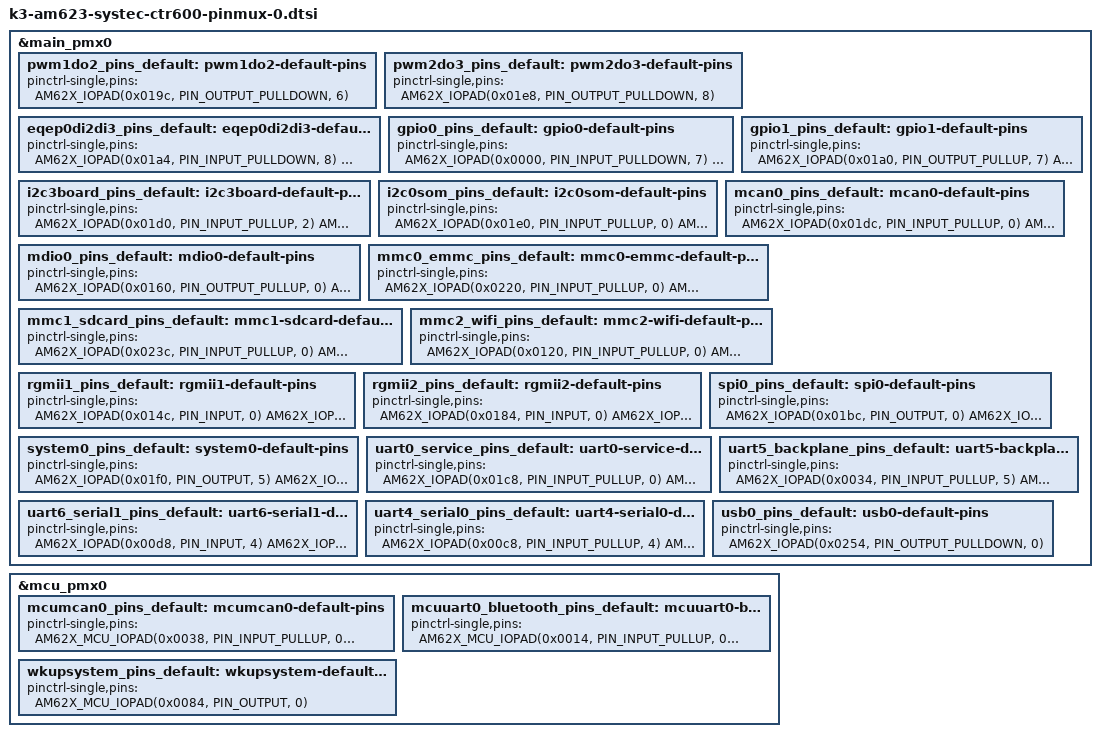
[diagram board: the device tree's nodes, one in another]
/* This file was auto-generated by TI PinMux on 17.10.2024 at 12:08:37. */
/* This file should only be used as a reference. Some pins/peripherals, */
/* depending on your use case, may need additional configuration. */

/* Some or all of the pins from the following groups are not used by the device tree
	ddr
	usb0
*/

&main_pmx0 {
	pwm1do2_pins_default: pwm1do2-default-pins {
		pinctrl-single,pins = <
			AM62X_IOPAD(0x019c, PIN_OUTPUT_PULLDOWN, 6) /* (B18) MCASP0_AXR1.EHRPWM1_A */
		>;
	};
	pwm2do3_pins_default: pwm2do3-default-pins {
		pinctrl-single,pins = <
			AM62X_IOPAD(0x01e8, PIN_OUTPUT_PULLDOWN, 8) /* (B17) I2C1_SCL.EHRPWM2_A */
		>;
	};
	eqep0di2di3_pins_default: eqep0di2di3-default-pins {
		pinctrl-single,pins = <
			AM62X_IOPAD(0x01a4, PIN_INPUT_PULLDOWN, 8) /* (B20) MCASP0_ACLKX.EQEP1_A */
			AM62X_IOPAD(0x01a8, PIN_INPUT_PULLDOWN, 8) /* (D20) MCASP0_AFSX.EQEP1_B */
		>;
	};
	gpio0_pins_default: gpio0-default-pins {
		pinctrl-single,pins = <
			AM62X_IOPAD(0x0000, PIN_INPUT_PULLDOWN, 7) /* (H24) OSPI0_CLK.GPIO0_0 */
			AM62X_IOPAD(0x0014, PIN_OUTPUT_PULLDOWN, 7) /* (F25) OSPI0_D2.GPIO0_5 */
			AM62X_IOPAD(0x0018, PIN_OUTPUT_PULLDOWN, 7) /* (F24) OSPI0_D3.GPIO0_6 */
			AM62X_IOPAD(0x001c, PIN_OUTPUT_PULLUP, 7) /* (J23) OSPI0_D4.GPIO0_7 */
			AM62X_IOPAD(0x002c, PIN_INPUT_PULLUP, 7) /* (F23) OSPI0_CSn0.GPIO0_11 */
			AM62X_IOPAD(0x0030, PIN_INPUT_PULLUP, 7) /* (G21) OSPI0_CSn1.GPIO0_12 */
			AM62X_IOPAD(0x004c, PIN_OUTPUT_PULLDOWN, 7) /* (P24) GPMC0_AD4.GPIO0_19 */
			AM62X_IOPAD(0x0050, PIN_OUTPUT_PULLDOWN, 7) /* (P22) GPMC0_AD5.GPIO0_20 */
			AM62X_IOPAD(0x0070, PIN_INPUT, 7) /* (T24) GPMC0_AD13.GPIO0_28 */
			AM62X_IOPAD(0x007c, PIN_OUTPUT, 7) /* (P25) GPMC0_CLK.GPIO0_31 */
			AM62X_IOPAD(0x0084, PIN_OUTPUT_PULLDOWN, 7) /* (L23) GPMC0_ADVn_ALE.GPIO0_32 */
			AM62X_IOPAD(0x0088, PIN_OUTPUT_PULLDOWN, 7) /* (L24) GPMC0_OEn_REn.GPIO0_33 */
			AM62X_IOPAD(0x008c, PIN_OUTPUT_PULLDOWN, 7) /* (L25) GPMC0_WEn.GPIO0_34 */
			AM62X_IOPAD(0x00b0, PIN_INPUT_PULLDOWN, 7) /* (K22) GPMC0_CSn2.GPIO0_43 */
			AM62X_IOPAD(0x00b8, PIN_INPUT_PULLDOWN, 7) /* (U22) VOUT0_DATA0.GPIO0_45 */
			AM62X_IOPAD(0x00bc, PIN_INPUT_PULLDOWN, 7) /* (V24) VOUT0_DATA1.GPIO0_46 */
			AM62X_IOPAD(0x00c0, PIN_INPUT_PULLDOWN, 7) /* (W25) VOUT0_DATA2.GPIO0_47 */
			AM62X_IOPAD(0x00c4, PIN_INPUT_PULLDOWN, 7) /* (W24) VOUT0_DATA3.GPIO0_48 */
			AM62X_IOPAD(0x00fc, PIN_INPUT_PULLUP, 7) /* (Y20) VOUT0_DE.GPIO0_62 */
			AM62X_IOPAD(0x0100, PIN_OUTPUT_PULLDOWN, 7) /* (AC25) VOUT0_VSYNC.GPIO0_63 */
			AM62X_IOPAD(0x0104, PIN_INPUT_PULLDOWN, 7) /* (AC24) VOUT0_PCLK.GPIO0_64 */
			AM62X_IOPAD(0x0124, PIN_OUTPUT_PULLDOWN, 7) /* (A23) MMC2_SDCD.GPIO0_71 */
			AM62X_IOPAD(0x0128, PIN_OUTPUT_PULLDOWN, 7) /* (B23) MMC2_SDWP.GPIO0_72 */
		>;
	};
	gpio1_pins_default: gpio1-default-pins {
		pinctrl-single,pins = <
			AM62X_IOPAD(0x01a0, PIN_OUTPUT_PULLUP, 7) /* (E18) MCASP0_AXR0.GPIO1_10 */
			AM62X_IOPAD(0x01b4, PIN_OUTPUT_PULLUP, 7) /* (A13) SPI0_CS0.GPIO1_15 */
			AM62X_IOPAD(0x01ec, PIN_OUTPUT_PULLUP, 7) /* (A17) I2C1_SDA.GPIO1_29 */
			AM62X_IOPAD(0x0244, PIN_OUTPUT_PULLDOWN, 7) /* (C17) MMC1_SDWP.GPIO1_49 */
			AM62X_IOPAD(0x0258, PIN_OUTPUT_PULLDOWN, 7) /* (F18) USB1_DRVVBUS.GPIO1_51 */
		>;
	};
	i2c3board_pins_default: i2c3board-default-pins {
		pinctrl-single,pins = <
			AM62X_IOPAD(0x01d0, PIN_INPUT_PULLUP, 2) /* (A15) UART0_CTSn.I2C3_SCL */
			AM62X_IOPAD(0x01d4, PIN_INPUT_PULLUP, 2) /* (B15) UART0_RTSn.I2C3_SDA */
		>;
	};
	i2c0som_pins_default: i2c0som-default-pins {
		pinctrl-single,pins = <
			AM62X_IOPAD(0x01e0, PIN_INPUT_PULLUP, 0) /* (B16) I2C0_SCL */
			AM62X_IOPAD(0x01e4, PIN_INPUT_PULLUP, 0) /* (A16) I2C0_SDA */
		>;
	};
	mcan0_pins_default: mcan0-default-pins {
		pinctrl-single,pins = <
			AM62X_IOPAD(0x01dc, PIN_INPUT_PULLUP, 0) /* (E15) MCAN0_RX */
			AM62X_IOPAD(0x01d8, PIN_OUTPUT, 0) /* (C15) MCAN0_TX */
		>;
	};
	mdio0_pins_default: mdio0-default-pins {
		pinctrl-single,pins = <
			AM62X_IOPAD(0x0160, PIN_OUTPUT_PULLUP, 0) /* (AD24) MDIO0_MDC */
			AM62X_IOPAD(0x015c, PIN_INPUT_PULLUP, 0) /* (AB22) MDIO0_MDIO */
		>;
	};
	mmc0_emmc_pins_default: mmc0-emmc-default-pins {
		pinctrl-single,pins = <
			AM62X_IOPAD(0x0220, PIN_INPUT_PULLUP, 0) /* (Y3) MMC0_CMD */
			AM62X_IOPAD(0x0218, PIN_OUTPUT, 0) /* (AB1) MMC0_CLK */
			AM62X_IOPAD(0x0214, PIN_INPUT_PULLUP, 0) /* (AA2) MMC0_DAT0 */
			AM62X_IOPAD(0x0210, PIN_INPUT_PULLUP, 0) /* (AA1) MMC0_DAT1 */
			AM62X_IOPAD(0x020c, PIN_INPUT_PULLUP, 0) /* (AA3) MMC0_DAT2 */
			AM62X_IOPAD(0x0208, PIN_INPUT_PULLUP, 0) /* (Y4) MMC0_DAT3 */
			AM62X_IOPAD(0x0204, PIN_INPUT_PULLUP, 0) /* (AB2) MMC0_DAT4 */
			AM62X_IOPAD(0x0200, PIN_INPUT_PULLUP, 0) /* (AC1) MMC0_DAT5 */
			AM62X_IOPAD(0x01fc, PIN_INPUT_PULLUP, 0) /* (AD2) MMC0_DAT6 */
			AM62X_IOPAD(0x01f8, PIN_INPUT_PULLUP, 0) /* (AC2) MMC0_DAT7 */
		>;
	};
	mmc1_sdcard_pins_default: mmc1-sdcard-default-pins {
		pinctrl-single,pins = <
			AM62X_IOPAD(0x023c, PIN_INPUT_PULLUP, 0) /* (A21) MMC1_CMD */
			AM62X_IOPAD(0x0234, PIN_OUTPUT, 0) /* (B22) MMC1_CLK */
			AM62X_IOPAD(0x0230, PIN_INPUT_PULLUP, 0) /* (A22) MMC1_DAT0 */
			AM62X_IOPAD(0x022c, PIN_INPUT_PULLUP, 0) /* (B21) MMC1_DAT1 */
			AM62X_IOPAD(0x0228, PIN_INPUT_PULLUP, 0) /* (C21) MMC1_DAT2 */
			AM62X_IOPAD(0x0224, PIN_INPUT_PULLUP, 0) /* (D22) MMC1_DAT3 */
			AM62X_IOPAD(0x0240, PIN_INPUT_PULLUP, 0) /* (D17) MMC1_SDCD */
		>;
	};
	mmc2_wifi_pins_default: mmc2-wifi-default-pins {
		pinctrl-single,pins = <
			AM62X_IOPAD(0x0120, PIN_INPUT_PULLUP, 0) /* (C24) MMC2_CMD */
			AM62X_IOPAD(0x0118, PIN_OUTPUT, 0) /* (D25) MMC2_CLK */
			AM62X_IOPAD(0x011C, PIN_INPUT, 0) /* () MMC2_CLKLB */
			AM62X_IOPAD(0x0114, PIN_INPUT_PULLUP, 0) /* (B24) MMC2_DAT0 */
			AM62X_IOPAD(0x0110, PIN_INPUT_PULLUP, 0) /* (C25) MMC2_DAT1 */
			AM62X_IOPAD(0x010c, PIN_INPUT_PULLUP, 0) /* (E23) MMC2_DAT2 */
			AM62X_IOPAD(0x0108, PIN_INPUT_PULLUP, 0) /* (D24) MMC2_DAT3 */
		>;
	};
	rgmii1_pins_default: rgmii1-default-pins {
		pinctrl-single,pins = <
			AM62X_IOPAD(0x014c, PIN_INPUT, 0) /* (AB17) RGMII1_RD0 */
			AM62X_IOPAD(0x0150, PIN_INPUT, 0) /* (AC17) RGMII1_RD1 */
			AM62X_IOPAD(0x0154, PIN_INPUT, 0) /* (AB16) RGMII1_RD2 */
			AM62X_IOPAD(0x0158, PIN_INPUT, 0) /* (AA15) RGMII1_RD3 */
			AM62X_IOPAD(0x0148, PIN_INPUT, 0) /* (AD17) RGMII1_RXC */
			AM62X_IOPAD(0x0144, PIN_INPUT, 0) /* (AE17) RGMII1_RX_CTL */
			AM62X_IOPAD(0x0134, PIN_OUTPUT, 0) /* (AE20) RGMII1_TD0 */
			AM62X_IOPAD(0x0138, PIN_OUTPUT, 0) /* (AD20) RGMII1_TD1 */
			AM62X_IOPAD(0x013c, PIN_OUTPUT, 0) /* (AE18) RGMII1_TD2 */
			AM62X_IOPAD(0x0140, PIN_OUTPUT, 0) /* (AD18) RGMII1_TD3 */
			AM62X_IOPAD(0x0130, PIN_OUTPUT, 0) /* (AE19) RGMII1_TXC */
			AM62X_IOPAD(0x012c, PIN_OUTPUT, 0) /* (AD19) RGMII1_TX_CTL */
		>;
	};
	rgmii2_pins_default: rgmii2-default-pins {
		pinctrl-single,pins = <
			AM62X_IOPAD(0x0184, PIN_INPUT, 0) /* (AE23) RGMII2_RD0 */
			AM62X_IOPAD(0x0188, PIN_INPUT, 0) /* (AB20) RGMII2_RD1 */
			AM62X_IOPAD(0x018c, PIN_INPUT, 0) /* (AC21) RGMII2_RD2 */
			AM62X_IOPAD(0x0190, PIN_INPUT, 0) /* (AE22) RGMII2_RD3 */
			AM62X_IOPAD(0x0180, PIN_INPUT, 0) /* (AD23) RGMII2_RXC */
			AM62X_IOPAD(0x017c, PIN_INPUT, 0) /* (AD22) RGMII2_RX_CTL */
			AM62X_IOPAD(0x016c, PIN_OUTPUT, 0) /* (Y18) RGMII2_TD0 */
			AM62X_IOPAD(0x0170, PIN_OUTPUT, 0) /* (AA18) RGMII2_TD1 */
			AM62X_IOPAD(0x0174, PIN_OUTPUT, 0) /* (AD21) RGMII2_TD2 */
			AM62X_IOPAD(0x0178, PIN_OUTPUT, 0) /* (AC20) RGMII2_TD3 */
			AM62X_IOPAD(0x0168, PIN_OUTPUT, 0) /* (AE21) RGMII2_TXC */
			AM62X_IOPAD(0x0164, PIN_OUTPUT, 0) /* (AA19) RGMII2_TX_CTL */
		>;
	};
	spi0_pins_default: spi0-default-pins {
		pinctrl-single,pins = <
			AM62X_IOPAD(0x01bc, PIN_OUTPUT, 0) /* (A14) SPI0_CLK */
			AM62X_IOPAD(0x01c0, PIN_OUTPUT, 0) /* (B13) SPI0_D0 */
			AM62X_IOPAD(0x01c4, PIN_INPUT_PULLUP, 0) /* (B14) SPI0_D1 */
		>;
	};
	system0_pins_default: system0-default-pins {
		pinctrl-single,pins = <
			AM62X_IOPAD(0x01f0, PIN_OUTPUT, 5) /* (A18) EXT_REFCLK1.CLKOUT0 */
			AM62X_IOPAD(0x01f4, PIN_INPUT, 0) /* (D16) EXTINTn */
			AM62X_IOPAD(0x0250, PIN_OUTPUT, 0) /* (E21) PORz_OUT */
			AM62X_IOPAD(0x024c, PIN_OUTPUT, 0) /* (F22) RESETSTATz */
			AM62X_IOPAD(0x0248, PIN_INPUT_PULLUP, 0) /* (F20) RESET_REQz */
		>;
	};
	uart0_service_pins_default: uart0-service-default-pins {
		pinctrl-single,pins = <
			AM62X_IOPAD(0x01c8, PIN_INPUT_PULLUP, 0) /* (D14) UART0_RXD */
			AM62X_IOPAD(0x01cc, PIN_OUTPUT_PULLUP, 0) /* (E14) UART0_TXD */
		>;
	};
	uart5_backplane_pins_default: uart5-backplane-default-pins {
		pinctrl-single,pins = <
			AM62X_IOPAD(0x0034, PIN_INPUT_PULLUP, 5) /* (H21) OSPI0_CSn2.UART5_RXD */
			AM62X_IOPAD(0x0038, PIN_OUTPUT_PULLUP, 5) /* (E24) OSPI0_CSn3.UART5_TXD */
			AM62X_IOPAD(0x0008, PIN_INPUT, 5) /* (J24) OSPI0_DQS.UART5_CTSn */
			AM62X_IOPAD(0x0004, PIN_OUTPUT, 5) /* (G25) OSPI0_LBCLKO.UART5_RTSn */
		>;
	};
	uart6_serial1_pins_default: uart6-serial1-default-pins {
		pinctrl-single,pins = <
			AM62X_IOPAD(0x00d8, PIN_INPUT, 4) /* (V21) VOUT0_DATA8.UART6_RXD */
			AM62X_IOPAD(0x00dc, PIN_OUTPUT, 4) /* (W21) VOUT0_DATA9.UART6_TXD */
		>;
	};
	uart4_serial0_pins_default: uart4-serial0-default-pins {
		pinctrl-single,pins = <
			AM62X_IOPAD(0x00c8, PIN_INPUT_PULLUP, 4) /* (Y25) VOUT0_DATA4.UART4_RXD */
			AM62X_IOPAD(0x00cc, PIN_OUTPUT_PULLUP, 4) /* (Y24) VOUT0_DATA5.UART4_TXD */
		>;
	};
	usb0_pins_default: usb0-default-pins {
		pinctrl-single,pins = <
			AM62X_IOPAD(0x0254, PIN_OUTPUT_PULLDOWN, 0) /* (C20) USB0_DRVVBUS */
		>;
	};
};


&mcu_pmx0 {
	mcumcan0_pins_default: mcumcan0-default-pins {
		pinctrl-single,pins = <
			AM62X_MCU_IOPAD(0x0038, PIN_INPUT_PULLUP, 0) /* (B3) MCU_MCAN0_RX */
			AM62X_MCU_IOPAD(0x0034, PIN_OUTPUT, 0) /* (D6) MCU_MCAN0_TX */
		>;
	};
	mcuuart0_bluetooth_pins_default: mcuuart0-bluetooth-default-pins {
		pinctrl-single,pins = <
			AM62X_MCU_IOPAD(0x0014, PIN_INPUT_PULLUP, 0) /* (B5) MCU_UART0_RXD */
			AM62X_MCU_IOPAD(0x0018, PIN_OUTPUT_PULLUP, 0) /* (A5) MCU_UART0_TXD */
			AM62X_MCU_IOPAD(0x001c, PIN_INPUT_PULLUP, 0) /* (A6) MCU_UART0_CTSn */
			AM62X_MCU_IOPAD(0x0020, PIN_OUTPUT_PULLUP, 0) /* (B6) MCU_UART0_RTSn */
		>;
	};
	wkupsystem_pins_default: wkupsystem-default-pins {
		pinctrl-single,pins = <
			AM62X_MCU_IOPAD(0x0084, PIN_OUTPUT, 0) /* (A12) WKUP_CLKOUT0 */
		>;
	};
};
